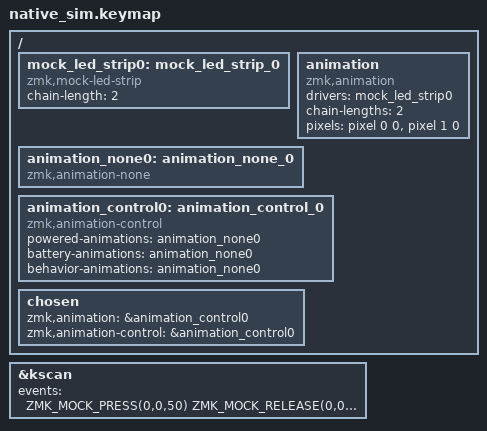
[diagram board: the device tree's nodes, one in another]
#include "../test.dtsi"
#include <dt-bindings/zmk/keys.h>
#include <dt-bindings/zmk/kscan_mock.h>
#include <zmk_driver_animation/animation.dtsi>

/ {
    mock_led_strip0: mock_led_strip_0 {
        compatible = "zmk,mock-led-strip";
        chain-length = <2>;
    };

    animation: animation {
        compatible = "zmk,animation";
        drivers = <&mock_led_strip0>;
        chain-lengths = <2>;
        pixels = <&pixel 0 0>, <&pixel 1 0>;
    };

    animation_none0: animation_none_0 {
        compatible = "zmk,animation-none";
    };

    /* See tests/engine for why this wraps animation_none0 (DESIGN.md #4
     * item 10: `zmk,animation` chosen must resolve to animation-control). */
    animation_control0: animation_control_0 {
        compatible = "zmk,animation-control";
        powered-animations = <&animation_none0>;
        battery-animations = <&animation_none0>;
        behavior-animations = <&animation_none0>;
    };

    chosen {
        zmk,animation = &animation_control0;
        zmk,animation-control = &animation_control0;
    };
};

/*
 * See tests/engine for why the default kscan mock event list needs
 * extending: simulated time must run past at least one tick period
 * (100ms at 10 FPS here) before native_sim exits.
 */
&kscan {
    events = <
    ZMK_MOCK_PRESS(0,0,50)
    ZMK_MOCK_RELEASE(0,0,50)
    ZMK_MOCK_PRESS(0,0,50)
    ZMK_MOCK_RELEASE(0,0,50)
    ZMK_MOCK_PRESS(0,0,50)
    ZMK_MOCK_RELEASE(0,0,50)
    >;
};
